VERSION ""

NS_ :

BS_:

BU_: HV HV HV CELLBOARD CELLBOARD HANDCART CELLBOARD HV BMS_HV MAINBOARD HV BMS_HV HV CELLBOARD BMS_HV MAINBOARD HV HANDCART MAINBOARD HV HANDCART HV MAINBOARD HANDCART HV BMS_HV CELLBOARD HV BMS_HV HV BMS_HV HV HANDCART HV HANDCART HV HV HANDCART HV BMS_HV HV BMS_HV HV HV HV BMS_HV HV HANDCART HV BMS_HV HANDCART CELLBOARD HV HV HV MAINBOARD HANDCART HV MAINBOARD HV HANDCART BMS_HV
VAL_TABLE_ _B9_Voltage_Channels 3 "3_Channels" 0 "0_Channels" ;
VAL_TABLE_ _B9_Supply_Voltage 1 "12__24_V_nominal_supply_voltage" ;
VAL_TABLE_ _B9_Current 2500 "2500_A" 1000 "1000_A" 500 "500_A" 300 "300_A" 100 "100_A" ;
VAL_TABLE_ _B9_Device_Type 2 "IVT_S" 1 "IVT_Mod" ;
VAL_TABLE_ VtDevice_Com 2 "CAN_2___not_terminated" 1 "CAN_1___terminated" 0 "none" ;
VAL_TABLE_ VtDevice_TOI 3 "I" ;
VAL_TABLE_ VtResetErrorLogdata 7 "Reset_error_current_implausible" 6 "Reset_error_Vref" 5 "Reset_error_Underflow_ADC_ch2" 4 "Reset_error_Overflow_ADC_ch2" 3 "Reset_error_Underflow_ADC_ch1" 2 "Reset_error_Overflow_ADC_ch1" 1 "Reset_error_ADC_interrupt" 0 "Reset_all_measurement_errors" ;
VAL_TABLE_ VtID_Result 8 "Vt_Result_Wh" 7 "Vt_Result_Ah" 6 "Vt_Result_W" 5 "Vt_Result_T" 4 "Vt_Result_U3" 3 "Vt_Result_U2" 2 "Vt_Result_U1" 1 "Vt_Result_I" 0 "Vt_Result_inaktive" ;
VAL_TABLE_ VtID_Cmd 54 "Set_THRESHOLD_neg" 53 "Set_THRESHOLD_pos" 52 "Set_MODE" 51 "START_OC_TEST" 50 "STORE" 49 "TRIGGER" 48 "Reset_Err_Log" 39 "Set_MODE_Result_Wh" 38 "Set_MODE_Result_Ah" 37 "Set_MODE_Result_W" 36 "Set_MODE_Result_T" 35 "Set_MODE_Result_U3" 34 "Set_MODE_Result_U2" 33 "Set_MODE_Result_U1" 32 "Set_MODE_Result_I" 31 "Set_CAN_ID_Cmd" 29 "Set_CAN_ID_Response" 23 "Set_CAN_ID_Result_Wh" 22 "Set_CAN_ID_Result_Ah" 21 "Set_CAN_ID_Result_W" 20 "Set_CAN_ID_Result_T" 19 "Set_CAN_ID_Result_U3" 18 "Set_CAN_ID_Result_U2" 17 "Set_CAN_ID_Result_U1" 16 "Set_CAN_ID_Result_I" ;
VAL_TABLE_ VtTriggerMode 2 "CYCLIC" 1 "TRIGGERED" 0 "DISABLED" ;
VAL_TABLE_ VtRunMode 1 "START" 0 "STOP" ;
VAL_TABLE_ VtID_Response 149 "ARTICLE_NUMBER" 148 "SERIAL_NUMBER" 147 "SW_VERSION" 146 "DEVICE_ID" 145 "STATUS" 143 "CAN_ID" 142 "STORE_to_default" 134 "START_OC_TEST" 133 "Description_for_the_value_'0x85'" 132 "THRESHOLD" 131 "CONFIG" 130 "MODE" 129 "STORE" 128 "TRIGGER" ;

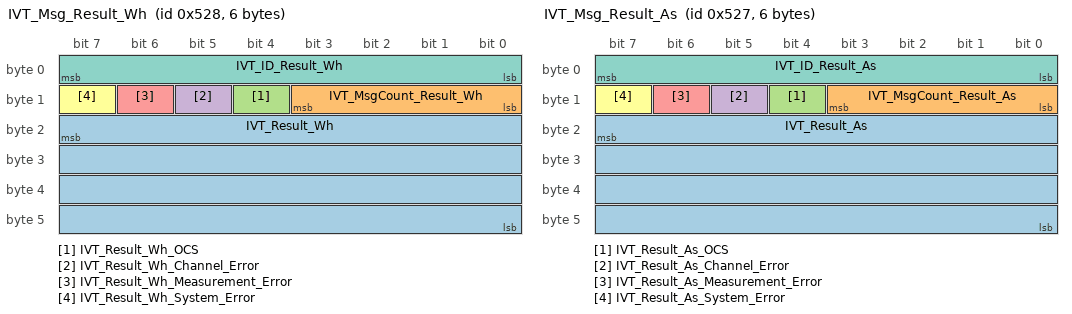
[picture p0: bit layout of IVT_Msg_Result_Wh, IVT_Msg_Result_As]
BO_ 1320 IVT_Msg_Result_Wh: 6 IVT_Mod
 SG_ IVT_Result_Wh : 23|32@0- (1,0) [-2147483648|2147483647] "Wh"  Host
 SG_ IVT_MsgCount_Result_Wh : 11|4@0+ (1,0) [0|0] ""  Host
 SG_ IVT_Result_Wh_OCS : 12|1@0+ (1,0) [0|0] "" Vector__XXX
 SG_ IVT_Result_Wh_Channel_Error : 13|1@0+ (1,0) [0|0] "" Vector__XXX
 SG_ IVT_Result_Wh_Measurement_Error : 14|1@0+ (1,0) [0|0] "" Vector__XXX
 SG_ IVT_Result_Wh_System_Error : 15|1@0+ (1,0) [0|0] "" Vector__XXX
 SG_ IVT_ID_Result_Wh : 7|8@0+ (1,0) [7|7] ""  Host

BO_ 1319 IVT_Msg_Result_As: 6 IVT_Mod
 SG_ IVT_Result_As : 23|32@0- (1,0) [-21474836478|2147483647] "As"  Host
 SG_ IVT_MsgCount_Result_As : 11|4@0+ (1,0) [0|0] ""  Host
 SG_ IVT_Result_As_OCS : 12|1@0+ (1,0) [0|0] "" Vector__XXX
 SG_ IVT_Result_As_Channel_Error : 13|1@0+ (1,0) [0|0] "" Vector__XXX
 SG_ IVT_Result_As_Measurement_Error : 14|1@0+ (1,0) [0|0] "" Vector__XXX
 SG_ IVT_Result_As_System_Error : 15|1@0+ (1,0) [0|0] "" Vector__XXX
 SG_ IVT_ID_Result_As : 7|8@0+ (1,0) [6|6] ""  Host

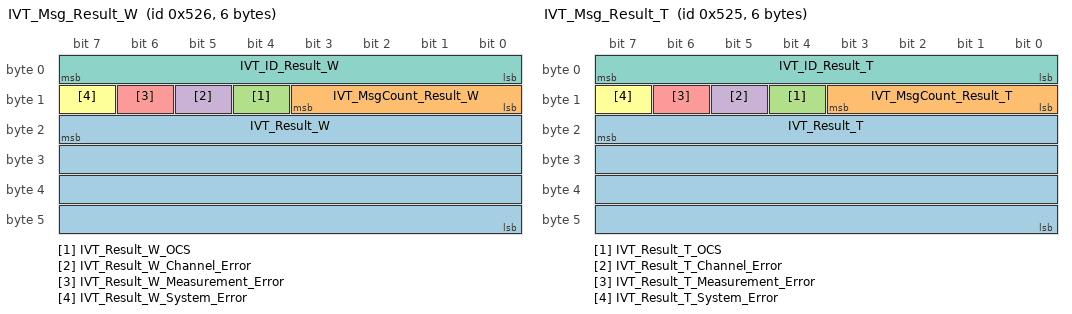
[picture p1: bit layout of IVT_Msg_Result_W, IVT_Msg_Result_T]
BO_ 1318 IVT_Msg_Result_W: 6 IVT_Mod
 SG_ IVT_Result_W : 23|32@0- (1,0) [-2147483648|2147483647] "W"  Host
 SG_ IVT_MsgCount_Result_W : 11|4@0+ (1,0) [0|0] ""  Host
 SG_ IVT_Result_W_OCS : 12|1@0+ (1,0) [0|0] "" Vector__XXX
 SG_ IVT_Result_W_Channel_Error : 13|1@0+ (1,0) [0|0] "" Vector__XXX
 SG_ IVT_Result_W_Measurement_Error : 14|1@0+ (1,0) [0|0] "" Vector__XXX
 SG_ IVT_Result_W_System_Error : 15|1@0+ (1,0) [0|0] "" Vector__XXX
 SG_ IVT_ID_Result_W : 7|8@0+ (1,0) [5|5] ""  Host

BO_ 1297 IVT_Msg_Response: 8 IVT_Mod
 SG_ _BA_Resp_SW_Ver_Internal m186 : 63|8@0+ (1,0) [0|0] "" Vector__XXX
 SG_ _B9_Resp_Device_V_supply m185 : 55|8@0+ (1,0) [0|0] "V" Vector__XXX
 SG_ _BA_Resp_SW_Ver_Day m186 : 55|8@0+ (1,0) [0|0] "" Vector__XXX
 SG_ _B9_Resp_Device_Com m185 : 47|8@0+ (1,0) [0|0] "" Vector__XXX
 SG_ _BA_Resp_SW_Ver_Month m186 : 40|8@1- (1,0) [0|0] "" Vector__XXX
 SG_ _B9_Resp_Device_TOI m185 : 39|8@0+ (1,0) [0|0] "" Vector__XXX
 SG_ _BA_Resp_SW_Ver_Vear m186 : 39|8@0+ (1,0) [0|0] "" Vector__XXX
 SG_ _B9_Resp_Device_Voltage_chan m185 : 27|4@0+ (1,0) [0|0] "" Vector__XXX
 SG_ _B6_Resp_OC_Neg_Reset_Threshold m182 : 31|16@0- (1,0) [0|0] "" Vector__XXX
 SG_ _B5_Resp_OC_Pos_Reset_Threshold m181 : 31|16@0- (1,0) [0|0] "" Vector__XXX
 SG_ _B4_Resp_Code_Level m180 : 31|16@0+ (1,0) [0|0] "" Vector__XXX
 SG_ _B0_Resp_Reset_Device_SN m176 : 31|32@0+ (1,0) [0|0] "" Vector__XXX
 SG_ _9F_Resp_Can_ID_SN_Response m159 : 31|32@0+ (1,0) [0|0] "" Vector__XXX
 SG_ _9D_Resp_Can_ID_SN_Command m157 : 31|32@0+ (1,0) [0|0] "" Vector__XXX
 SG_ _97_Resp_Can_ID_SN_Wh m151 : 31|32@0+ (1,0) [0|0] "" Vector__XXX
 SG_ _96_Resp_Can_ID_SN_As m150 : 31|32@0+ (1,0) [0|0] "" Vector__XXX
 SG_ _95_Resp_Can_ID_SN_W m149 : 31|32@0+ (1,0) [0|0] "" Vector__XXX
 SG_ _94_Resp_Can_ID_SN_T m148 : 31|32@0+ (1,0) [0|0] "" Vector__XXX
 SG_ _93_Resp_Can_ID_SN_U3 m147 : 31|32@0+ (1,0) [0|0] "" Vector__XXX
 SG_ _92_Resp_Can_ID_SN_U2 m146 : 31|32@0+ (1,0) [0|0] "" Vector__XXX
 SG_ _91_Resp_Can_ID_SN_U1 m145 : 31|32@0+ (1,0) [0|0] "" Vector__XXX
 SG_ _90_Resp_Can_ID_SN_I m144 : 31|32@0+ (1,0) [0|0] "" Vector__XXX
 SG_ _BA_Resp_SW_Ver_Revision m186 : 31|8@0+ (1,0) [0|0] "" Vector__XXX
 SG_ _BF_Restart_Alive_SN m191 : 31|32@0+ (1,0) [0|0] "" Vector__XXX
 SG_ _B4_Resp_Startup_Mode m180 : 16|1@0+ (1,0) [0|0] "" Vector__XXX
 SG_ _B1_00_Trigger_I m177 : 16|1@0+ (1,0) [0|0] "" Vector__XXX
 SG_ _B1_01_Trigger_U1 m177 : 17|1@0+ (1,0) [0|0] "" Vector__XXX
 SG_ _B1_02_Trigger_U2 m177 : 18|1@0+ (1,0) [0|0] "" Vector__XXX
 SG_ _B1_03_Trigger_U3 m177 : 19|1@0+ (1,0) [0|0] "" Vector__XXX
 SG_ _B1_04_Trigger_T m177 : 20|1@0+ (1,0) [0|0] "" Vector__XXX
 SG_ _B1_05_Trigger_W m177 : 21|1@0+ (1,0) [0|0] "" Vector__XXX
 SG_ _B1_06_Trigger_As m177 : 22|1@0+ (1,0) [0|0] "" Vector__XXX
 SG_ _A7_Resp_CycleTime_WH m167 : 23|16@0+ (1,0) [0|0] "ms" Vector__XXX
 SG_ _A6_Resp_CycleTime_As m166 : 23|16@0+ (1,0) [0|0] "ms" Vector__XXX
 SG_ _A5_Resp_CycleTime_W m165 : 23|16@0+ (1,0) [0|0] "ms" Vector__XXX
 SG_ _A4_Resp_CycleTime_T m164 : 23|16@0+ (1,0) [0|0] "ms" Vector__XXX
 SG_ _A3_Resp_CycleTime_U3 m163 : 23|16@0+ (1,0) [0|0] "ms" Vector__XXX
 SG_ _A2_Resp_CycleTime_U2 m162 : 23|16@0+ (1,0) [0|0] "ms" Vector__XXX
 SG_ _A1_Resp_CycleTime_U1 m161 : 23|16@0+ (1,0) [0|0] "ms" Vector__XXX
 SG_ _A0_Resp_CycleTime_I m160 : 23|16@0+ (1,0) [0|0] "ms" Vector__XXX
 SG_ _83_Resp_LogData_Counter m131 : 23|48@0+ (1,0) [0|0] "" Vector__XXX
 SG_ _82_Resp_AllLogData_Counter m130 : 23|48@0+ (1,0) [0|0] "" Vector__XXX
 SG_ _81_Resp_SystemError_Count_Mask m129 : 23|16@0+ (1,0) [0|0] "" Vector__XXX
 SG_ _80_Resp_MeasError_Count_Mask m128 : 23|16@0+ (1,0) [0|0] "" Vector__XXX
 SG_ _B9_Resp_Device_current m185 : 23|12@0+ (1,0) [0|0] "A" Vector__XXX
 SG_ _BA_Resp_SW_Ver_Minor m186 : 23|8@0+ (1,0) [0|0] "" Vector__XXX
 SG_ _B2_Resp_Store_Device_SN m178 : 23|32@0+ (1,0) [0|0] "" Vector__XXX
 SG_ _B1_07_Trigger_WH m177 : 23|1@0+ (1,0) [0|0] "" Vector__XXX
 SG_ _B4_Resp_Actual_Mode m180 : 8|1@0+ (1,0) [0|0] "" Vector__XXX
 SG_ _A7_Resp_TriggerMode_WH m167 : 9|2@0+ (1,0) [0|2] "" Vector__XXX
 SG_ _A6_Resp_TriggerMode_As m166 : 9|2@0+ (1,0) [0|2] "" Vector__XXX
 SG_ _A5_Resp_TriggerMode_W m165 : 9|2@0+ (1,0) [0|2] "" Vector__XXX
 SG_ _A4_Resp_TriggerMode_T m164 : 9|2@0+ (1,0) [0|2] "" Vector__XXX
 SG_ _A3_Resp_TriggerMode_U3 m163 : 9|2@0+ (1,0) [0|2] "" Vector__XXX
 SG_ _A2_Resp_TriggerMode_U2 m162 : 9|2@0+ (1,0) [0|2] "" Vector__XXX
 SG_ _A1_Resp_TriggerMode_U1 m161 : 9|2@0+ (1,0) [0|2] "" Vector__XXX
 SG_ _A0_Resp_TriggerMode_I m160 : 9|2@0+ (1,0) [0|2] "" Vector__XXX
 SG_ _A7_Resp_Endianess_WH m167 : 14|1@0+ (1,0) [0|0] "" Vector__XXX
 SG_ _A6_Resp_Endianess_As m166 : 14|1@0+ (1,0) [0|0] "" Vector__XXX
 SG_ _A5_Resp_Endianess_W m165 : 14|1@0+ (1,0) [0|0] "" Vector__XXX
 SG_ _A4_Resp_Endianess_T m164 : 14|1@0+ (1,0) [0|0] "" Vector__XXX
 SG_ _A3_Resp_Endianess_U3 m163 : 14|1@0+ (1,0) [0|0] "" Vector__XXX
 SG_ _A2_Resp_Endianess_U2 m162 : 14|1@0+ (1,0) [0|0] "" Vector__XXX
 SG_ _A1_Resp_Endianess_U1 m161 : 14|1@0+ (1,0) [0|0] "" Vector__XXX
 SG_ _A0_Resp_Endianess_I m160 : 14|1@0+ (1,0) [0|0] "" Vector__XXX
 SG_ _BC_Resp_Art_N m188 : 15|56@0+ (1,0) [0|0] "" Vector__XXX
 SG_ _BB_Resp_Serien_Nr m187 : 15|32@0+ (1,0) [0|0] "" Vector__XXX
 SG_ _BA_Resp_SW_Ver_Major_HW m186 : 15|8@0+ (1,0) [0|0] "" Vector__XXX
 SG_ _B9_Resp_Device_type m185 : 15|8@0+ (1,0) [0|0] "" Vector__XXX
 SG_ _B6_Resp_OC_Neg_Set_Threshold m182 : 15|16@0- (1,0) [0|0] "" Vector__XXX
 SG_ _B5_Resp_OC_Pos_Set_Threshold m181 : 15|16@0- (1,0) [0|0] "" Vector__XXX
 SG_ _B3_Resp_Oc_Test_Time m179 : 15|16@0+ (1,0) [0|65535] "ms" Vector__XXX
 SG_ _B2_Resp_Store_dummy m178 : 15|8@0+ (1,0) [0|0] "" Vector__XXX
 SG_ _B0_Resp_Reset_Item m176 : 15|16@0+ (1,0) [0|0] "" Vector__XXX
 SG_ _A7_Resp_Sign_WH m167 : 15|1@0+ (1,0) [0|0] "" Vector__XXX
 SG_ _A6_Resp_Sign_As m166 : 15|1@0+ (1,0) [0|0] "" Vector__XXX
 SG_ _A5_Resp_Sign_W m165 : 15|1@0+ (1,0) [0|0] "" Vector__XXX
 SG_ _A4_Resp_Sign_T m164 : 15|1@0+ (1,0) [0|0] "" Vector__XXX
 SG_ _A3_Resp_Sign_U3 m163 : 15|1@0+ (1,0) [0|0] "" Vector__XXX
 SG_ _A2_Resp_Sign_U2 m162 : 15|1@0+ (1,0) [0|0] "" Vector__XXX
 SG_ _A1_Resp_Sign_U1 m161 : 15|1@0+ (1,0) [0|0] "" Vector__XXX
 SG_ _A0_Resp_Sign_I m160 : 15|1@0+ (1,0) [0|0] "" Vector__XXX
 SG_ _9F_Resp_Can_ID_val_Response m159 : 15|16@0+ (1,0) [0|0] "" Vector__XXX
 SG_ _9D_Resp_Can_ID_val_Command m157 : 15|16@0+ (1,0) [0|0] "" Vector__XXX
 SG_ _97_Resp_Can_ID_val_Wh m151 : 15|16@0+ (1,0) [0|0] "" Vector__XXX
 SG_ _96_Resp_Can_ID_val_As m150 : 15|16@0+ (1,0) [0|0] "" Vector__XXX
 SG_ _95_Resp_Can_ID_val_W m149 : 15|16@0+ (1,0) [0|0] "" Vector__XXX
 SG_ _94_Resp_Can_ID_val_T m148 : 15|16@0+ (1,0) [0|0] "" Vector__XXX
 SG_ _93_Resp_Can_ID_val_U3 m147 : 15|16@0+ (1,0) [0|0] "" Vector__XXX
 SG_ _92_Resp_Can_ID_val_U2 m146 : 15|16@0+ (1,0) [0|0] "" Vector__XXX
 SG_ _91_Resp_Can_ID_val_U1 m145 : 15|16@0+ (1,0) [0|0] "" Vector__XXX
 SG_ _90_Resp_Can_ID_val_I m144 : 15|16@0+ (1,0) [0|0] "" Vector__XXX
 SG_ _83_Resp_LogData_Item m131 : 15|8@0+ (1,0) [0|0] "" Vector__XXX
 SG_ _82_Resp_AllLogData_Item m130 : 15|8@0+ (1,0) [0|0] "" Vector__XXX
 SG_ _81_Resp_SystemError_Item m129 : 15|8@0+ (1,0) [0|0] "" Vector__XXX
 SG_ _80_Resp_MeasError_Item m128 : 15|8@0+ (1,0) [0|0] "" Vector__XXX
 SG_ _BF_Restart_Alive_Cmd_ID m191 : 15|16@0+ (1,0) [0|0] "" Vector__XXX
 SG_ _FF_Wrong_Command m255 : 15|8@0+ (1,0) [0|0] "" Vector__XXX
 SG_ _B1_Trigger_spare m177 : 15|8@0+ (1,0) [0|0] "" Vector__XXX
 SG_ IVT_ID_Response M : 7|8@0+ (1,0) [0|0] ""  Host

BO_ 1317 IVT_Msg_Result_T: 6 IVT_Mod
 SG_ IVT_Result_T : 23|32@0- (0.1,0) [-2147483648|2147483647] "Â°C"  Host
 SG_ IVT_MsgCount_Result_T : 11|4@0+ (1,0) [0|0] ""  Host
 SG_ IVT_Result_T_OCS : 12|1@0+ (1,0) [0|0] "" Vector__XXX
 SG_ IVT_Result_T_Channel_Error : 13|1@0+ (1,0) [0|0] "" Vector__XXX
 SG_ IVT_Result_T_Measurement_Error : 14|1@0+ (1,0) [0|0] "" Vector__XXX
 SG_ IVT_Result_T_System_Error : 15|1@0+ (1,0) [0|0] "" Vector__XXX
 SG_ IVT_ID_Result_T : 7|8@0+ (1,0) [4|4] ""  Host

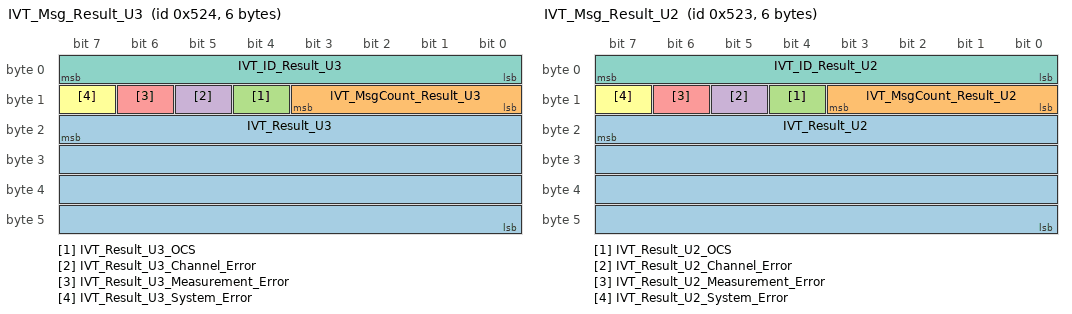
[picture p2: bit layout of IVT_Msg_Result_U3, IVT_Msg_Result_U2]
BO_ 1316 IVT_Msg_Result_U3: 6 IVT_Mod
 SG_ IVT_Result_U3 : 23|32@0- (1,0) [-2147483648|2147483647] "mV"  Host
 SG_ IVT_MsgCount_Result_U3 : 11|4@0+ (1,0) [0|0] ""  Host
 SG_ IVT_Result_U3_OCS : 12|1@0+ (1,0) [0|0] "" Vector__XXX
 SG_ IVT_Result_U3_Channel_Error : 13|1@0+ (1,0) [0|0] "" Vector__XXX
 SG_ IVT_Result_U3_Measurement_Error : 14|1@0+ (1,0) [0|0] "" Vector__XXX
 SG_ IVT_Result_U3_System_Error : 15|1@0+ (1,0) [0|0] "" Vector__XXX
 SG_ IVT_ID_Result_U3 : 7|8@0+ (1,0) [3|3] ""  Host

BO_ 1315 IVT_Msg_Result_U2: 6 IVT_Mod
 SG_ IVT_Result_U2 : 23|32@0- (1,0) [-2147483648|2147483647] "mV"  Host
 SG_ IVT_MsgCount_Result_U2 : 11|4@0+ (1,0) [0|0] ""  Host
 SG_ IVT_Result_U2_OCS : 12|1@0+ (1,0) [0|0] "" Vector__XXX
 SG_ IVT_Result_U2_Channel_Error : 13|1@0+ (1,0) [0|0] "" Vector__XXX
 SG_ IVT_Result_U2_Measurement_Error : 14|1@0+ (1,0) [0|0] "" Vector__XXX
 SG_ IVT_Result_U2_System_Error : 15|1@0+ (1,0) [0|0] "" Vector__XXX
 SG_ IVT_ID_Result_U2 : 7|8@0+ (1,0) [2|2] ""  Host

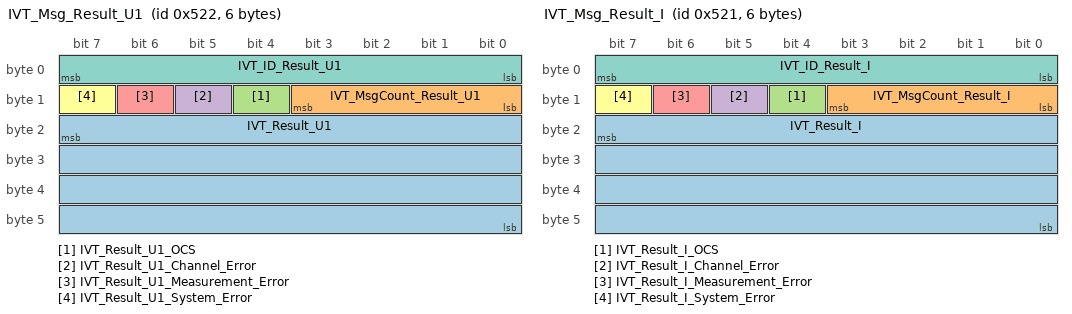
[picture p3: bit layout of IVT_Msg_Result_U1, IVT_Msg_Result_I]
BO_ 1314 IVT_Msg_Result_U1: 6 IVT_Mod
 SG_ IVT_Result_U1 : 23|32@0- (1,0) [-2147483648|2147483647] "mV"  Host
 SG_ IVT_MsgCount_Result_U1 : 11|4@0+ (1,0) [0|0] ""  Host
 SG_ IVT_Result_U1_OCS : 12|1@0+ (1,0) [0|0] "" Vector__XXX
 SG_ IVT_Result_U1_Channel_Error : 13|1@0+ (1,0) [0|0] "" Vector__XXX
 SG_ IVT_Result_U1_Measurement_Error : 14|1@0+ (1,0) [0|0] "" Vector__XXX
 SG_ IVT_Result_U1_System_Error : 15|1@0+ (1,0) [0|0] "" Vector__XXX
 SG_ IVT_ID_Result_U1 : 7|8@0+ (1,0) [1|1] ""  Host

BO_ 1313 IVT_Msg_Result_I: 6 IVT_Mod
 SG_ IVT_Result_I : 23|32@0- (1,0) [-2147483648|2147483647] "mA"  Host
 SG_ IVT_MsgCount_Result_I : 11|4@0+ (1,0) [0|0] ""  Host
 SG_ IVT_Result_I_OCS : 12|1@0+ (1,0) [0|0] "" Vector__XXX
 SG_ IVT_Result_I_Channel_Error : 13|1@0+ (1,0) [0|0] "" Vector__XXX
 SG_ IVT_Result_I_Measurement_Error : 14|1@0+ (1,0) [0|0] "" Vector__XXX
 SG_ IVT_Result_I_System_Error : 15|1@0+ (1,0) [0|0] "" Vector__XXX
 SG_ IVT_ID_Result_I : 7|8@0+ (1,0) [0|0] ""  Host

BO_ 1041 IVT_Msg_Cmd: 8 Host
 SG_ _5F_Get_Can_ID_SN_Response m95 : 31|32@0+ (1,0) [0|0] "" Vector__XXX
 SG_ _5D_Get_Can_ID_SN_Command m93 : 31|32@0+ (1,0) [0|0] "" Vector__XXX
 SG_ _57_Get_Can_ID_SN_Wh m87 : 31|32@0+ (1,0) [0|0] "" Vector__XXX
 SG_ _56_Get_Can_ID_SN_As m86 : 31|32@0+ (1,0) [0|0] "" Vector__XXX
 SG_ _55_Get_Can_ID_SN_W m85 : 31|32@0+ (1,0) [0|0] "" Vector__XXX
 SG_ _54_Get_Can_ID_SN_T m84 : 31|32@0+ (1,0) [0|0] "" Vector__XXX
 SG_ _53_Get_Can_ID_SN_U3 m83 : 31|32@0+ (1,0) [0|0] "" Vector__XXX
 SG_ _52_Get_Can_ID_SN_U2 m82 : 31|32@0+ (1,0) [0|0] "" Vector__XXX
 SG_ _51_Get_Can_ID_SN_U1 m81 : 31|32@0+ (1,0) [0|0] "" Vector__XXX
 SG_ _50_Get_Can_ID_SN_I m80 : 31|32@0+ (1,0) [0|0] "" Vector__XXX
 SG_ _36_OC_Neg_Reset_Threshold m54 : 31|16@0- (1,0) [0|0] "A" Vector__XXX
 SG_ _35_OC_Pos_Reset_Threshold m53 : 31|16@0- (1,0) [0|0] "A" Vector__XXX
 SG_ _34_Code_Level m52 : 31|16@0+ (1,0) [0|0] "" Vector__XXX
 SG_ _30_Reset_Device_SN m48 : 31|32@0+ (1,0) [0|0] "" Vector__XXX
 SG_ _1F_Set_Can_ID_SN_Response m31 : 31|32@0+ (1,0) [0|0] "" Vector__XXX
 SG_ _1D_Set_Can_ID_SN_Command m29 : 31|32@0+ (1,0) [0|0] "" Vector__XXX
 SG_ _17_Set_Can_ID_SN_Wh m23 : 31|32@0+ (1,0) [0|0] "" Vector__XXX
 SG_ _16_Set_Can_ID_SN_As m22 : 31|32@0+ (1,0) [0|0] "" Vector__XXX
 SG_ _15_Set_Can_ID_SN_W m21 : 31|32@0+ (1,0) [0|0] "" Vector__XXX
 SG_ _14_Set_Can_ID_SN_T m20 : 31|32@0+ (1,0) [0|0] "" Vector__XXX
 SG_ _13_Set_Can_ID_SN_U3 m19 : 31|32@0+ (1,0) [0|0] "" Vector__XXX
 SG_ _12_Set_Can_ID_SN_U2 m18 : 31|32@0+ (1,0) [0|0] "" Vector__XXX
 SG_ _11_Set_Can_ID_SN_U1 m17 : 31|32@0+ (1,0) [0|0] "" Vector__XXX
 SG_ _10_Set_Can_ID_SN_I m16 : 31|32@0+ (1,0) [0|0] "" Vector__XXX
 SG_ _34_Startup_Mode m52 : 16|1@0+ (1,0) [0|0] "" Vector__XXX
 SG_ _31_00_Trigger_I m49 : 16|1@0+ (1,0) [0|0] "" Vector__XXX
 SG_ _31_01_Trigger_U1 m49 : 17|1@0+ (1,0) [0|0] "" Vector__XXX
 SG_ _31_02_Trigger_U2 m49 : 18|1@0+ (1,0) [0|0] "" Vector__XXX
 SG_ _31_03_Trigger_U3 m49 : 19|1@0+ (1,0) [0|0] "" Vector__XXX
 SG_ _31_04_Trigger_T m49 : 20|1@0+ (1,0) [0|0] "" Vector__XXX
 SG_ _31_05_Trigger_W m49 : 21|1@0+ (1,0) [0|0] "" Vector__XXX
 SG_ _31_06_Trigger_As m49 : 22|1@0+ (1,0) [0|0] "" Vector__XXX
 SG_ _27_Conf_CycleTime_WH m39 : 23|16@0+ (1,0) [0|0] "ms" Vector__XXX
 SG_ _26_Conf_CycleTime_As m38 : 23|16@0+ (1,0) [0|0] "ms" Vector__XXX
 SG_ _25_Conf_CycleTime_W m37 : 23|16@0+ (1,0) [0|0] "ms" Vector__XXX
 SG_ _24_Conf_CycleTime_T m36 : 23|16@0+ (1,0) [0|0] "ms" Vector__XXX
 SG_ _23_Conf_CycleTime_U3 m35 : 23|16@0+ (1,0) [0|0] "ms" Vector__XXX
 SG_ _22_Conf_CycleTime_U2 m34 : 23|16@0+ (1,0) [0|0] "ms" Vector__XXX
 SG_ _21_Conf_CycleTime_U1 m33 : 23|16@0+ (1,0) [0|0] "ms" Vector__XXX
 SG_ _20_Conf_CycleTime_I m32 : 23|16@0+ (1,0) [0|0] "ms" Vector__XXX
 SG_ _31_07_Trigger_WH m49 : 23|1@0+ (1,0) [0|0] "" Vector__XXX
 SG_ _34_Actual_Mode m52 : 8|1@0+ (1,0) [0|0] "" Vector__XXX
 SG_ _27_Conf_TriggerMode_WH m39 : 9|2@0+ (1,0) [0|2] "" Vector__XXX
 SG_ _26_Conf_TriggerMode_As m38 : 9|2@0+ (1,0) [0|2] "" Vector__XXX
 SG_ _25_Conf_TriggerMode_W m37 : 9|2@0+ (1,0) [0|2] "" Vector__XXX
 SG_ _24_Conf_TriggerMode_T m36 : 9|2@0+ (1,0) [0|2] "" Vector__XXX
 SG_ _23_Conf_TriggerMode_U3 m35 : 9|2@0+ (1,0) [0|2] "" Vector__XXX
 SG_ _22_Conf_TriggerMode_U2 m34 : 9|2@0+ (1,0) [0|2] "" Vector__XXX
 SG_ _21_Conf_TriggerMode_U1 m33 : 9|2@0+ (1,0) [0|2] "" Vector__XXX
 SG_ _20_Conf_TriggerMode_I m32 : 9|2@0+ (1,0) [0|2] "" Vector__XXX
 SG_ _27_Conf_Endianess_WH m39 : 14|1@0+ (1,0) [0|0] "" Vector__XXX
 SG_ _26_Conf_Endianess_As m38 : 14|1@0+ (1,0) [0|0] "" Vector__XXX
 SG_ _25_Conf_Endianess_W m37 : 14|1@0+ (1,0) [0|0] "" Vector__XXX
 SG_ _24_Conf_Endianess_T m36 : 14|1@0+ (1,0) [0|0] "" Vector__XXX
 SG_ _23_Conf_Endianess_U3 m35 : 14|1@0+ (1,0) [0|0] "" Vector__XXX
 SG_ _22_Conf_Endianess_U2 m34 : 14|1@0+ (1,0) [0|0] "" Vector__XXX
 SG_ _21_Conf_Endianess_U1 m33 : 14|1@0+ (1,0) [0|0] "" Vector__XXX
 SG_ _20_Conf_Endianess_I m32 : 14|1@0+ (1,0) [0|0] "" Vector__XXX
 SG_ _7C_Get_Art_Nr_dummy m124 : 15|8@0+ (1,0) [0|0] "" Vector__XXX
 SG_ _7B_Get_Serien_Nr_dummy m123 : 15|8@0+ (1,0) [0|0] "" Vector__XXX
 SG_ _7A_Get_SW_Version_dummy m122 : 15|8@0+ (1,0) [0|0] "" Vector__XXX
 SG_ _79_Get_Device_Id_dummy m121 : 15|8@0+ (1,0) [0|0] "" Vector__XXX
 SG_ _76_Get_OC_Neg_dummy m118 : 15|8@0+ (1,0) [0|0] "" Vector__XXX
 SG_ _75_Get_OC_Pos_dummy m117 : 15|8@0+ (1,0) [0|0] "" Vector__XXX
 SG_ _74_Get_Mode_dummy m116 : 15|8@0+ (1,0) [0|0] "" Vector__XXX
 SG_ _73_Get_OC_Test_dummy m115 : 15|8@0+ (1,0) [0|0] "" Vector__XXX
 SG_ _67_Get_Result_dummy_Wh m103 : 15|8@0+ (1,0) [0|0] "" Vector__XXX
 SG_ _66_Get_Result_dummy_As m102 : 15|8@0+ (1,0) [0|0] "" Vector__XXX
 SG_ _65_Get_Result_dummy_W m101 : 15|8@0+ (1,0) [0|0] "" Vector__XXX
 SG_ _64_Get_Result_dummy_T m100 : 15|8@0+ (1,0) [0|0] "" Vector__XXX
 SG_ _63_Get_Result_dummy_U3 m99 : 15|8@0+ (1,0) [0|0] "" Vector__XXX
 SG_ _62_Get_Result_dummy_U2 m98 : 15|8@0+ (1,0) [0|0] "" Vector__XXX
 SG_ _61_Get_Result_dummy_U1 m97 : 15|8@0+ (1,0) [0|0] "" Vector__XXX
 SG_ _60_Get_Result_dummy_I m96 : 15|8@0+ (1,0) [0|0] "" Vector__XXX
 SG_ _43_Get_LogData_Item m67 : 15|8@0+ (1,0) [0|0] "" Vector__XXX
 SG_ _42_Get_AllLogData_Item m66 : 15|8@0+ (1,0) [0|0] "" Vector__XXX
 SG_ _41_Get_SystemError_Item m65 : 15|8@0+ (1,0) [0|0] "" Vector__XXX
 SG_ _40_Get_MeasError_Item m64 : 15|8@0+ (1,0) [0|0] "" Vector__XXX
 SG_ _3F_Restart_Dummy m63 : 15|8@0+ (1,0) [0|0] "" Vector__XXX
 SG_ _3D_Restart_Default_Dummy m61 : 15|8@0+ (1,0) [0|0] "" Vector__XXX
 SG_ _3A_RESTART_to_Bitrate m58 : 15|8@0+ (1,0) [0|0] "" Vector__XXX
 SG_ _36_OC_Neg_Set_Threshold m54 : 15|16@0- (1,0) [0|0] "A" Vector__XXX
 SG_ _35_OC_Pos_Set_Threshold m53 : 15|16@0- (1,0) [0|0] "A" Vector__XXX
 SG_ _33_Oc_Test_Time m51 : 15|16@0+ (1,0) [0|65535] "ms" Vector__XXX
 SG_ _32_Store_dummy m50 : 15|8@0+ (1,0) [0|0] "" Vector__XXX
 SG_ _30_Reset_Item m48 : 15|16@0+ (1,0) [0|0] "" Vector__XXX
 SG_ _27_Conf_Sign_WH m39 : 15|1@0+ (1,0) [0|0] "" Vector__XXX
 SG_ _26_Conf_Sign_As m38 : 15|1@0+ (1,0) [0|0] "" Vector__XXX
 SG_ _25_Conf_Sign_W m37 : 15|1@0+ (1,0) [0|0] "" Vector__XXX
 SG_ _24_Conf_Sign_T m36 : 15|1@0+ (1,0) [0|0] "" Vector__XXX
 SG_ _23_Conf_Sign_U3 m35 : 15|1@0+ (1,0) [0|0] "" Vector__XXX
 SG_ _22_Conf_Sign_U2 m34 : 15|1@0+ (1,0) [0|0] "" Vector__XXX
 SG_ _21_Conf_Sign_U1 m33 : 15|1@0+ (1,0) [0|0] "" Vector__XXX
 SG_ _20_Conf_Sign_I m32 : 15|1@0+ (1,0) [0|0] "" Vector__XXX
 SG_ _1F_Set_Can_ID_val_Response m31 : 15|16@0+ (1,0) [0|2047] "" Vector__XXX
 SG_ _1D_Set_Can_ID_val_Command m29 : 15|16@0+ (1,0) [0|2047] "" Vector__XXX
 SG_ _17_Set_Can_ID_val_Wh m23 : 15|16@0+ (1,0) [0|2047] "" Vector__XXX
 SG_ _16_Set_Can_ID_val_As m22 : 15|16@0+ (1,0) [0|2047] "" Vector__XXX
 SG_ _15_Set_Can_ID_val_W m21 : 15|16@0+ (1,0) [0|2047] "" Vector__XXX
 SG_ _14_Set_Can_ID_val_T m20 : 15|16@0+ (1,0) [0|2047] "" Vector__XXX
 SG_ _13_Set_Can_ID_val_U3 m19 : 15|16@0+ (1,0) [0|2047] "" Vector__XXX
 SG_ _12_Set_Can_ID_val_U2 m18 : 15|16@0+ (1,0) [0|2047] "" Vector__XXX
 SG_ _11_Set_Can_ID_val_U1 m17 : 15|16@0+ (1,0) [0|2047] "" Vector__XXX
 SG_ _10_Set_Can_ID_val_I m16 : 15|16@0+ (1,0) [0|2047] ""  IVT_Mod
 SG_ _31_Trigger_spare m49 : 15|8@0+ (1,0) [0|0] "" Vector__XXX
 SG_ IVT_ID_Cmd M : 7|8@0+ (1,0) [0|0] ""  IVT_Mod

BO_ 1026 BOARD_STATUS: 4 Vector__XXX
 SG_ balancing_cells_CELL17 : 30|1@1+ (1,0) [0|1] "" Vector__XXX
 SG_ balancing_cells_CELL16 : 29|1@1+ (1,0) [0|1] "" Vector__XXX
 SG_ balancing_cells_CELL15 : 28|1@1+ (1,0) [0|1] "" Vector__XXX
 SG_ balancing_cells_CELL14 : 27|1@1+ (1,0) [0|1] "" Vector__XXX
 SG_ balancing_cells_CELL13 : 26|1@1+ (1,0) [0|1] "" Vector__XXX
 SG_ balancing_cells_CELL12 : 25|1@1+ (1,0) [0|1] "" Vector__XXX
 SG_ balancing_cells_CELL11 : 24|1@1+ (1,0) [0|1] "" Vector__XXX
 SG_ balancing_cells_CELL10 : 23|1@1+ (1,0) [0|1] "" Vector__XXX
 SG_ balancing_cells_CELL9 : 22|1@1+ (1,0) [0|1] "" Vector__XXX
 SG_ balancing_cells_CELL8 : 21|1@1+ (1,0) [0|1] "" Vector__XXX
 SG_ balancing_cells_CELL7 : 20|1@1+ (1,0) [0|1] "" Vector__XXX
 SG_ balancing_cells_CELL6 : 19|1@1+ (1,0) [0|1] "" Vector__XXX
 SG_ balancing_cells_CELL5 : 18|1@1+ (1,0) [0|1] "" Vector__XXX
 SG_ balancing_cells_CELL4 : 17|1@1+ (1,0) [0|1] "" Vector__XXX
 SG_ balancing_cells_CELL3 : 16|1@1+ (1,0) [0|1] "" Vector__XXX
 SG_ balancing_cells_CELL2 : 15|1@1+ (1,0) [0|1] "" Vector__XXX
 SG_ balancing_cells_CELL1 : 14|1@1+ (1,0) [0|1] "" Vector__XXX
 SG_ balancing_cells_CELL0 : 13|1@1+ (1,0) [0|1] "" Vector__XXX
 SG_ balancing_status : 12|1@1+ (1,0) [0|1] "" Vector__XXX
 SG_ errors_OPEN_WIRE : 11|1@1+ (1,0) [0|1] "" Vector__XXX
 SG_ errors_TEMP_COMM_5 : 10|1@1+ (1,0) [0|1] "" Vector__XXX
 SG_ errors_TEMP_COMM_4 : 9|1@1+ (1,0) [0|1] "" Vector__XXX
 SG_ errors_TEMP_COMM_3 : 8|1@1+ (1,0) [0|1] "" Vector__XXX
 SG_ errors_TEMP_COMM_2 : 7|1@1+ (1,0) [0|1] "" Vector__XXX
 SG_ errors_TEMP_COMM_1 : 6|1@1+ (1,0) [0|1] "" Vector__XXX
 SG_ errors_TEMP_COMM_0 : 5|1@1+ (1,0) [0|1] "" Vector__XXX
 SG_ errors_LTC_COMM : 4|1@1+ (1,0) [0|1] "" Vector__XXX
 SG_ errors_CAN_COMM : 3|1@1+ (1,0) [0|1] "" Vector__XXX
 SG_ cellboard_id : 0|3@1+ (1,0) [0|7] "" Vector__XXX

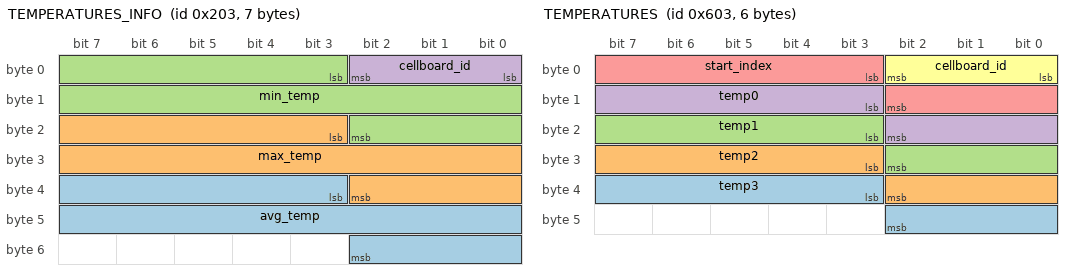
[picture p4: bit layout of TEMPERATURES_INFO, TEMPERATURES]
BO_ 515 TEMPERATURES_INFO: 7 Vector__XXX
 SG_ avg_temp : 35|16@1+ (0.0015259021896696422,-20) [-20|80] "" Vector__XXX
 SG_ max_temp : 19|16@1+ (0.0015259021896696422,-20) [-20|80] "" Vector__XXX
 SG_ min_temp : 3|16@1+ (0.0015259021896696422,-20) [-20|80] "" Vector__XXX
 SG_ cellboard_id : 0|3@1+ (1,0) [0|7] "" Vector__XXX

BO_ 1539 TEMPERATURES: 6 Vector__XXX
 SG_ temp3 : 35|8@1+ (0.39215686274509803,-20) [-20|80] "" Vector__XXX
 SG_ temp2 : 27|8@1+ (0.39215686274509803,-20) [-20|80] "" Vector__XXX
 SG_ temp1 : 19|8@1+ (0.39215686274509803,-20) [-20|80] "" Vector__XXX
 SG_ temp0 : 11|8@1+ (0.39215686274509803,-20) [-20|80] "" Vector__XXX
 SG_ start_index : 3|8@1+ (1,0) [0|255] "" Vector__XXX
 SG_ cellboard_id : 0|3@1+ (1,0) [0|7] "" Vector__XXX

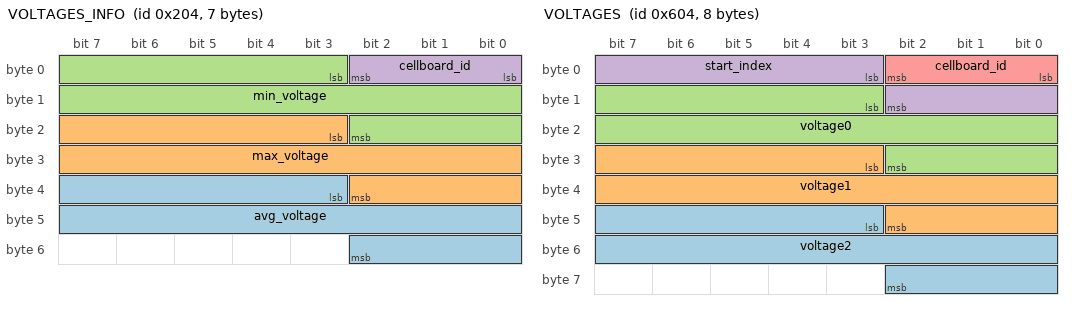
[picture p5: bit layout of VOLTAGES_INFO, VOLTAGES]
BO_ 516 VOLTAGES_INFO: 7 Vector__XXX
 SG_ avg_voltage : 35|16@1+ (7.629510948348211e-05,0) [0|5] "" Vector__XXX
 SG_ max_voltage : 19|16@1+ (7.629510948348211e-05,0) [0|5] "" Vector__XXX
 SG_ min_voltage : 3|16@1+ (7.629510948348211e-05,0) [0|5] "" Vector__XXX
 SG_ cellboard_id : 0|3@1+ (1,0) [0|7] "" Vector__XXX

BO_ 1540 VOLTAGES: 8 Vector__XXX
 SG_ voltage2 : 43|16@1+ (7.629510948348211e-05,0) [0|5] "" Vector__XXX
 SG_ voltage1 : 27|16@1+ (7.629510948348211e-05,0) [0|5] "" Vector__XXX
 SG_ voltage0 : 11|16@1+ (7.629510948348211e-05,0) [0|5] "" Vector__XXX
 SG_ start_index : 3|8@1+ (1,0) [0|255] "" Vector__XXX
 SG_ cellboard_id : 0|3@1+ (1,0) [0|7] "" Vector__XXX

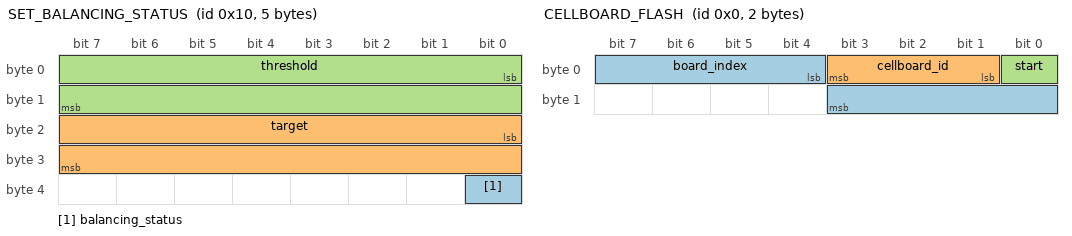
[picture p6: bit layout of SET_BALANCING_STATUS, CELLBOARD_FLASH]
BO_ 16 SET_BALANCING_STATUS: 5 Vector__XXX
 SG_ balancing_status : 32|1@1+ (1,0) [0|1] "" Vector__XXX
 SG_ target : 16|16@1+ (1,0) [0|65535] "" Vector__XXX
 SG_ threshold : 0|16@1+ (1,0) [0|65535] "" Vector__XXX

BO_ 5 FLASH_CELLBOARD_0_RX: 0 Vector__XXX

BO_ 6 FLASH_CELLBOARD_1_TX: 0 Vector__XXX

BO_ 7 FLASH_CELLBOARD_1_RX: 0 Vector__XXX

BO_ 8 FLASH_CELLBOARD_2_TX: 0 Vector__XXX

BO_ 9 FLASH_CELLBOARD_2_RX: 0 Vector__XXX

BO_ 10 FLASH_CELLBOARD_3_TX: 0 Vector__XXX

BO_ 11 FLASH_CELLBOARD_3_RX: 0 Vector__XXX

BO_ 12 FLASH_CELLBOARD_4_TX: 0 Vector__XXX

BO_ 13 FLASH_CELLBOARD_4_RX: 0 Vector__XXX

BO_ 14 FLASH_CELLBOARD_5_TX: 0 Vector__XXX

BO_ 15 FLASH_CELLBOARD_5_RX: 0 Vector__XXX

BO_ 0 CELLBOARD_FLASH: 2 Vector__XXX
 SG_ board_index : 4|8@1+ (1,0) [0|255] "" Vector__XXX
 SG_ cellboard_id : 1|3@1+ (1,0) [0|7] "" Vector__XXX
 SG_ start : 0|1@1+ (1,0) [0|1] "" Vector__XXX

BO_ 1 CELLBOARD_FLASH_TX: 0 Vector__XXX

BO_ 2 CELLBOARD_FLASH_RX: 0 Vector__XXX

BO_ 3 CELLBOARD_FLASH_REQUEST: 1 Vector__XXX
 SG_ cellboard_id : 1|3@1+ (1,0) [0|7] "" Vector__XXX
 SG_ mainboard : 0|1@1+ (1,0) [0|1] "" Vector__XXX

BO_ 4 CELLBOARD_FLASH_RESPONSE: 1 Vector__XXX
 SG_ ready : 3|1@1+ (1,0) [0|1] "" Vector__XXX
 SG_ cellboard_id : 0|3@1+ (1,0) [0|7] "" Vector__XXX

BO_ 1537 CELLBOARD_DISCOVERY: 1 Vector__XXX
 SG_ cellboard_id : 0|3@1+ (1,0) [0|7] "" Vector__XXX

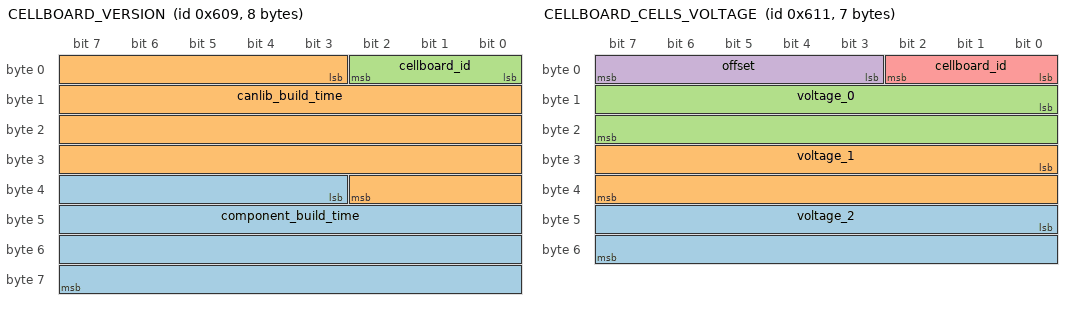
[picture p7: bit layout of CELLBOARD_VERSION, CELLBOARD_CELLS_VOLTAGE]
BO_ 1545 CELLBOARD_VERSION: 8 Vector__XXX
 SG_ component_build_time : 35|29@1+ (1,0) [0|536870911] "" Vector__XXX
 SG_ canlib_build_time : 3|32@1+ (1,0) [0|4294967295] "" Vector__XXX
 SG_ cellboard_id : 0|3@1+ (1,0) [0|7] "" Vector__XXX

BO_ 513 CELLBOARD_STATUS: 1 Vector__XXX
 SG_ status : 3|3@1+ (1,0) [0|7] "" Vector__XXX
 SG_ cellboard_id : 0|3@1+ (1,0) [0|7] "" Vector__XXX

BO_ 1553 CELLBOARD_CELLS_VOLTAGE: 7 Vector__XXX
 SG_ voltage_2 : 40|16@1+ (7.629510948348211e-05,0) [0|5] "" Vector__XXX
 SG_ voltage_1 : 24|16@1+ (7.629510948348211e-05,0) [0|5] "" Vector__XXX
 SG_ voltage_0 : 8|16@1+ (7.629510948348211e-05,0) [0|5] "" Vector__XXX
 SG_ offset : 3|5@1+ (1,0) [0|21] "" Vector__XXX
 SG_ cellboard_id : 0|3@1+ (1,0) [0|7] "" Vector__XXX

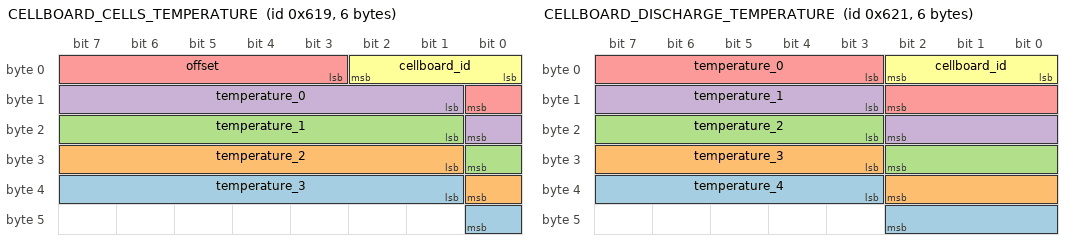
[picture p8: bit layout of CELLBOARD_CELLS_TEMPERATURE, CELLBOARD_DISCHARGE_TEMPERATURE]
BO_ 1561 CELLBOARD_CELLS_TEMPERATURE: 6 Vector__XXX
 SG_ temperature_3 : 33|8@1+ (0.49019607843137253,-25.0) [-25.0|100.0] "" Vector__XXX
 SG_ temperature_2 : 25|8@1+ (0.49019607843137253,-25.0) [-25.0|100.0] "" Vector__XXX
 SG_ temperature_1 : 17|8@1+ (0.49019607843137253,-25.0) [-25.0|100.0] "" Vector__XXX
 SG_ temperature_0 : 9|8@1+ (0.49019607843137253,-25.0) [-25.0|100.0] "" Vector__XXX
 SG_ offset : 3|6@1+ (1,0) [0|44] "" Vector__XXX
 SG_ cellboard_id : 0|3@1+ (1,0) [0|7] "" Vector__XXX

BO_ 1569 CELLBOARD_DISCHARGE_TEMPERATURE: 6 Vector__XXX
 SG_ temperature_4 : 35|8@1+ (0.49019607843137253,-25.0) [-25.0|100.0] "" Vector__XXX
 SG_ temperature_3 : 27|8@1+ (0.49019607843137253,-25.0) [-25.0|100.0] "" Vector__XXX
 SG_ temperature_2 : 19|8@1+ (0.49019607843137253,-25.0) [-25.0|100.0] "" Vector__XXX
 SG_ temperature_1 : 11|8@1+ (0.49019607843137253,-25.0) [-25.0|100.0] "" Vector__XXX
 SG_ temperature_0 : 3|8@1+ (0.49019607843137253,-25.0) [-25.0|100.0] "" Vector__XXX
 SG_ cellboard_id : 0|3@1+ (1,0) [0|7] "" Vector__XXX

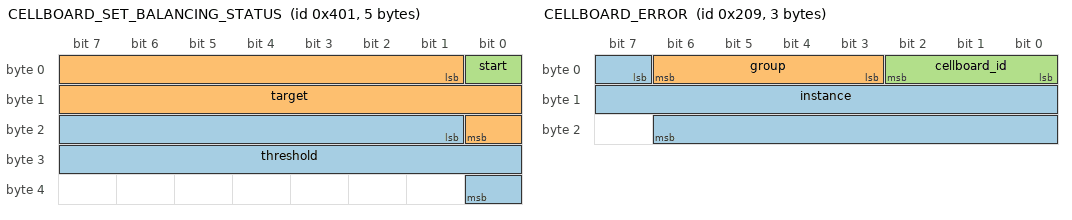
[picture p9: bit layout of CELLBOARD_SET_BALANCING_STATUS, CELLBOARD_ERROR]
BO_ 1025 CELLBOARD_SET_BALANCING_STATUS: 5 Vector__XXX
 SG_ threshold : 17|16@1+ (2.9755092698558025e-06,0.005) [0.005|0.2] "" Vector__XXX
 SG_ target : 1|16@1+ (2.1362630655374995e-05,2.8) [2.8|4.2] "" Vector__XXX
 SG_ start : 0|1@1+ (1,0) [0|1] "" Vector__XXX

BO_ 1577 CELLBOARD_BALANCING_STATUS: 4 Vector__XXX
 SG_ discharging_cell_23 : 28|1@1+ (1,0) [0|1] "" Vector__XXX
 SG_ discharging_cell_22 : 27|1@1+ (1,0) [0|1] "" Vector__XXX
 SG_ discharging_cell_21 : 26|1@1+ (1,0) [0|1] "" Vector__XXX
 SG_ discharging_cell_20 : 25|1@1+ (1,0) [0|1] "" Vector__XXX
 SG_ discharging_cell_19 : 24|1@1+ (1,0) [0|1] "" Vector__XXX
 SG_ discharging_cell_18 : 23|1@1+ (1,0) [0|1] "" Vector__XXX
 SG_ discharging_cell_17 : 22|1@1+ (1,0) [0|1] "" Vector__XXX
 SG_ discharging_cell_16 : 21|1@1+ (1,0) [0|1] "" Vector__XXX
 SG_ discharging_cell_15 : 20|1@1+ (1,0) [0|1] "" Vector__XXX
 SG_ discharging_cell_14 : 19|1@1+ (1,0) [0|1] "" Vector__XXX
 SG_ discharging_cell_13 : 18|1@1+ (1,0) [0|1] "" Vector__XXX
 SG_ discharging_cell_12 : 17|1@1+ (1,0) [0|1] "" Vector__XXX
 SG_ discharging_cell_11 : 16|1@1+ (1,0) [0|1] "" Vector__XXX
 SG_ discharging_cell_10 : 15|1@1+ (1,0) [0|1] "" Vector__XXX
 SG_ discharging_cell_9 : 14|1@1+ (1,0) [0|1] "" Vector__XXX
 SG_ discharging_cell_8 : 13|1@1+ (1,0) [0|1] "" Vector__XXX
 SG_ discharging_cell_7 : 12|1@1+ (1,0) [0|1] "" Vector__XXX
 SG_ discharging_cell_6 : 11|1@1+ (1,0) [0|1] "" Vector__XXX
 SG_ discharging_cell_5 : 10|1@1+ (1,0) [0|1] "" Vector__XXX
 SG_ discharging_cell_4 : 9|1@1+ (1,0) [0|1] "" Vector__XXX
 SG_ discharging_cell_3 : 8|1@1+ (1,0) [0|1] "" Vector__XXX
 SG_ discharging_cell_2 : 7|1@1+ (1,0) [0|1] "" Vector__XXX
 SG_ discharging_cell_1 : 6|1@1+ (1,0) [0|1] "" Vector__XXX
 SG_ discharging_cell_0 : 5|1@1+ (1,0) [0|1] "" Vector__XXX
 SG_ cellboard_id : 2|3@1+ (1,0) [0|7] "" Vector__XXX
 SG_ status : 0|2@1+ (1,0) [0|3] "" Vector__XXX

BO_ 521 CELLBOARD_ERROR: 3 Vector__XXX
 SG_ instance : 7|16@1+ (1,0) [0|65535] "" Vector__XXX
 SG_ group : 3|4@1+ (1,0) [0|15] "" Vector__XXX
 SG_ cellboard_id : 0|3@1+ (1,0) [0|7] "" Vector__XXX

CM_ BO_ 1026 "[LEGACY]: Cellboard's status";
CM_ BO_ 515 "[LEGACY]: Cellboard temperature precalculated values";
CM_ BO_ 1539 "[LEGACY]: Cells' temperatures";
CM_ BO_ 516 "[LEGACY]: Cellboard voltages precalculated values";
CM_ BO_ 1540 "[LEGACY]: Cells' voltages";
CM_ BO_ 16 "[LEGACY]: Set balancing status for cells";
CM_ BO_ 5 "[LEGACY]: Used by Bootcommander";
CM_ BO_ 6 "[LEGACY]: Used by Bootcommander";
CM_ BO_ 7 "[LEGACY]: Used by Bootcommander";
CM_ BO_ 8 "[LEGACY]: Used by Bootcommander";
CM_ BO_ 9 "[LEGACY]: Used by Bootcommander";
CM_ BO_ 10 "[LEGACY]: Used by Bootcommander";
CM_ BO_ 11 "[LEGACY]: Used by Bootcommander";
CM_ BO_ 12 "[LEGACY]: Used by Bootcommander";
CM_ BO_ 13 "[LEGACY]: Used by Bootcommander";
CM_ BO_ 14 "[LEGACY]: Used by Bootcommander";
CM_ BO_ 15 "[LEGACY]: Used by Bootcommander";
CM_ BO_ 0 "Start or stop the actual flash procedure, need a request first";
CM_ BO_ 1 "Flash data transmitted from the master to the cellboards";
CM_ BO_ 2 "Flash data received by the master from the cellboards";
CM_ BO_ 3 "Cellboard flash procedure start request";
CM_ BO_ 4 "Cellboard flash procedure ACK";
CM_ BO_ 1537 "Message used to check if the communication between nodes in the network is working correctly";
CM_ BO_ 1545 "Cellboard version: build-time timestamp and canlib build-time timestamp";
CM_ BO_ 513 "Cellboard internal FSM status";
CM_ BO_ 1553 "Cellboard cells voltages in V";
CM_ BO_ 1561 "Cellboard cells temperatures in Â°C";
CM_ BO_ 1569 "Cellboard discharge resistor temperatures in Â°C";
CM_ BO_ 1025 "Start or stop the balancing procedure, if started needs to be sent continuously";
CM_ BO_ 1577 "Info about the cells that are currently discharging";
CM_ BO_ 521 "Info regarding the error which has occured";
BA_DEF_ BU_  "Manufacturer" STRING ;
BA_DEF_ BU_  "ILUsed" ENUM  "No","Yes";
BA_DEF_ BO_  "NmMessage" ENUM  "no","yes";
BA_DEF_ BO_  "GenMsgILSupport" ENUM  "No","Yes";
BA_DEF_  "NmBaseAddress" HEX 1024 1087;
BA_DEF_  "BusType" STRING ;
BA_DEF_ BO_  "GenMsgCycleTime" INT 0 1000;
BA_DEF_ BO_  "GenMsgSendType" ENUM  "Cyclic","NotUsed","NotUsed","NotUsed","NotUsed","Cyclic","NotUsed","IfActive","NoMsgSendType","NotUsed","vector_leerstring";
BA_DEF_ SG_  "GenSigSendType" ENUM  "Cyclic","OnWrite","OnWriteWithRepetition","OnChange","OnChangeWithRepetition","IfActive","IfActiveWithRepetition","NoSigSendType","NotUsed","NotUsed","NotUsed","NotUsed","NotUsed";
BA_DEF_ SG_  "GenSigStartValue" FLOAT 0 100000000000;
BA_DEF_DEF_  "Manufacturer" "Isabellenhuette";
BA_DEF_DEF_  "ILUsed" "Yes";
BA_DEF_DEF_  "NmMessage" "no";
BA_DEF_DEF_  "GenMsgILSupport" "Yes";
BA_DEF_DEF_  "NmBaseAddress" 1024;
BA_DEF_DEF_  "BusType" "CAN";
BA_DEF_DEF_  "GenMsgCycleTime" 0;
BA_DEF_DEF_  "GenMsgSendType" "NoMsgSendType";
BA_DEF_DEF_  "GenSigSendType" "OnWrite";
BA_DEF_DEF_  "GenSigStartValue" 0;
BA_ "GenMsgSendType" BO_ 1320 1;
BA_ "GenSigSendType" SG_ 1320 IVT_Result_Wh 7;
BA_ "GenSigSendType" SG_ 1320 IVT_ID_Result_Wh 7;
BA_ "GenSigStartValue" SG_ 1320 IVT_ID_Result_Wh 7;
BA_ "GenMsgSendType" BO_ 1319 1;
BA_ "GenSigSendType" SG_ 1319 IVT_ID_Result_As 7;
BA_ "GenSigStartValue" SG_ 1319 IVT_ID_Result_As 6;
BA_ "GenMsgSendType" BO_ 1318 1;
BA_ "GenSigSendType" SG_ 1318 IVT_ID_Result_W 7;
BA_ "GenSigStartValue" SG_ 1318 IVT_ID_Result_W 5;
BA_ "GenMsgSendType" BO_ 1297 1;
BA_ "GenSigStartValue" SG_ 1297 _A7_Resp_TriggerMode_WH 2;
BA_ "GenSigStartValue" SG_ 1297 _A6_Resp_TriggerMode_As 2;
BA_ "GenSigStartValue" SG_ 1297 _A5_Resp_TriggerMode_W 2;
BA_ "GenSigStartValue" SG_ 1297 _A4_Resp_TriggerMode_T 2;
BA_ "GenSigStartValue" SG_ 1297 _A0_Resp_TriggerMode_I 2;
BA_ "GenMsgSendType" BO_ 1317 1;
BA_ "GenSigSendType" SG_ 1317 IVT_ID_Result_T 7;
BA_ "GenSigStartValue" SG_ 1317 IVT_ID_Result_T 4;
BA_ "GenMsgSendType" BO_ 1316 1;
BA_ "GenSigSendType" SG_ 1316 IVT_ID_Result_U3 7;
BA_ "GenSigStartValue" SG_ 1316 IVT_ID_Result_U3 3;
BA_ "GenMsgSendType" BO_ 1315 1;
BA_ "GenSigSendType" SG_ 1315 IVT_ID_Result_U2 7;
BA_ "GenSigStartValue" SG_ 1315 IVT_ID_Result_U2 2;
BA_ "GenMsgSendType" BO_ 1314 1;
BA_ "GenSigSendType" SG_ 1314 IVT_Result_U1 7;
BA_ "GenSigSendType" SG_ 1314 IVT_ID_Result_U1 7;
BA_ "GenSigStartValue" SG_ 1314 IVT_ID_Result_U1 1;
BA_ "GenMsgSendType" BO_ 1313 1;
BA_ "GenSigSendType" SG_ 1313 IVT_Result_I 7;
BA_ "GenSigSendType" SG_ 1313 IVT_ID_Result_I 7;
BA_ "GenMsgSendType" BO_ 1041 7;
BA_ "NmMessage" BO_ 1041 1;
BA_ "GenSigStartValue" SG_ 1041 _27_Conf_TriggerMode_WH 2;
BA_ "GenSigStartValue" SG_ 1041 _26_Conf_TriggerMode_As 2;
BA_ "GenSigStartValue" SG_ 1041 _25_Conf_TriggerMode_W 2;
BA_ "GenSigStartValue" SG_ 1041 _24_Conf_TriggerMode_T 2;
BA_ "GenSigStartValue" SG_ 1041 _20_Conf_TriggerMode_I 2;
BA_ "GenMsgCycleTime" BO_ 0 200;
BA_ "GenMsgCycleTime" BO_ 1545 1000;
BA_ "GenMsgCycleTime" BO_ 513 20;
BA_ "GenMsgCycleTime" BO_ 1553 50;
BA_ "GenMsgCycleTime" BO_ 1561 50;
BA_ "GenMsgCycleTime" BO_ 1569 50;
BA_ "GenMsgCycleTime" BO_ 1025 200;
BA_ "GenMsgCycleTime" BO_ 1577 50;
BA_ "GenMsgCycleTime" BO_ 521 20;
VAL_ 1320 IVT_ID_Result_Wh 7 "Vt_Result_Wh" ;
VAL_ 1319 IVT_ID_Result_As 6 "Vt_Result_As" ;
VAL_ 1318 IVT_ID_Result_W 5 "Vt_Result_W" ;
VAL_ 1297 _B9_Resp_Device_V_supply 1 "12__24_V_nominal_supply_voltage" ;
VAL_ 1297 _B9_Resp_Device_Com 2 "CAN_2___not_terminated" 1 "CAN_1___terminated" 0 "none" ;
VAL_ 1297 _B9_Resp_Device_TOI 3 "I" ;
VAL_ 1297 _B9_Resp_Device_Voltage_chan 3 "3_Channels" 0 "0_Channels" ;
VAL_ 1297 _B4_Resp_Startup_Mode 1 "Run" 0 "Stop" ;
VAL_ 1297 _B9_Resp_Device_current 2500 "2500_A" 1000 "1000_A" 500 "500_A" 300 "300_A" 100 "100_A" ;
VAL_ 1297 _B4_Resp_Actual_Mode 1 "RUN" 0 "STOP" ;
VAL_ 1297 _A7_Resp_TriggerMode_WH 2 "CYCLIC" 1 "TRIGGERED" 0 "DISABLED" ;
VAL_ 1297 _A6_Resp_TriggerMode_As 2 "CYCLIC" 1 "TRIGGERED" 0 "DISABLED" ;
VAL_ 1297 _A5_Resp_TriggerMode_W 2 "CYCLIC" 1 "TRIGGERED" 0 "DISABLED" ;
VAL_ 1297 _A4_Resp_TriggerMode_T 2 "CYCLIC" 1 "TRIGGERED" 0 "DISABLED" ;
VAL_ 1297 _A3_Resp_TriggerMode_U3 2 "CYCLIC" 1 "TRIGGERED" 0 "DISABLED" ;
VAL_ 1297 _A2_Resp_TriggerMode_U2 2 "CYCLIC" 1 "TRIGGERED" 0 "DISABLED" ;
VAL_ 1297 _A1_Resp_TriggerMode_U1 2 "CYCLIC" 1 "TRIGGERED" 0 "DISABLED" ;
VAL_ 1297 _A0_Resp_TriggerMode_I 2 "CYCLIC" 1 "TRIGGERED" 0 "DISABLED" ;
VAL_ 1297 _B9_Resp_Device_type 2 "IVT_S" 1 "IVT_Mod" ;
VAL_ 1297 _B0_Resp_Reset_Item 554 "Reset_temp_minimum" 553 "Reset_temp_maximum" 552 "Reset_U3_minimum" 551 "Reset_U3_maximum" 550 "Reset_U2_minimum" 549 "Reset_U2_maximum" 548 "Reset_U1_minimum" 547 "Reset_U1_maximum" 546 "Reset_Current_minimum" 545 "Reset_Current_maximum" 540 "Reset_Run_overcur_neg_activated" 539 "Reset_Run_overcur_pos_activated" 538 "Reset_Run_temp_out_spec_limits" 537 "Reset_Run_temp_in_spec_limits" 536 "Reset_Run_volt_3_out_spec_limits" 535 "Reset_Run_volt_3_in_spec_limits" 534 "Reset_Run_volt_2_out_spec_limits" 533 "Reset_Run_volt_2_in_spec_limits" 532 "Reset_Run_volt_1_out_spec_limits" 531 "Reset_Run_volt_1_in_spec_limits" 530 "Reset_Run_cur_out_spec_limits" 529 "Reset_Run_cur_in_spec_limits" 528 "Reset_Runtime_overall" 518 "Reset_Energy_counter_discharging" 517 "Reset_Energy_counter_charging" 516 "Reset_Energy_counter_overall" 515 "Reset_Ah_counter_discharging" 514 "Reset_Ah_counter_charging" 513 "Reset_Ah_counter_overall" 512 "Reset_all_Logdata_Since_Reset" 272 "Reset_Reset_EMC" 271 "Reset_Reset_Watchdog" 270 "Reset_illegal_opcode" 269 "Reset_ADC_Clock" 268 "Reset_eeprom_rw" 267 "Reset_overcurrent_detection" 266 "Reset_configuration" 265 "Reset_system_init" 264 "Reset_system_clock" 263 "Reset_power_failure" 262 "Reset_undertemp" 261 "Reset_overtemp" 260 "Reset_CAN_bus_transmit_Data" 259 "Reset_CAN_bus_receive_Data" 258 "Reset_Parameter_CRC" 257 "Reset_Code_CRC" 256 "Reset_all_System_errors" 15 "Reset_calibration_data_" 14 "Reset_ntc_I_OpenCircuit" 13 "Reset_ntc_h_OpenCircuit" 12 "Reset_voltage_measU3_OpenCircuit" 11 "Reset_voltage_measU2_OpenCircuit" 10 "Reset_voltage_measU1_OpenCircuit" 9 "Reset_current_measI1_OpenCircuit" 8 "Reset_thermal_EMF_correction" 7 "Reset_error_current_implausible" 6 "Reset_error_Vref" 5 "Reset_error_Underflow_ADC_ch2" 4 "Reset_error_Overflow_ADC_ch2" 3 "Reset_error_Underflow_ADC_ch1" 2 "Reset_error_Overflow_ADC_ch1" 1 "Reset_error_ADC_interrupt" 0 "Reset_all_measurement_errors" ;
VAL_ 1297 _83_Resp_LogData_Item 42 "Resp_temp_minimum" 41 "Resp_temp_maxmimum" 40 "Resp_U3_minimum" 39 "Resp_U3_maximum" 38 "Resp_U2_minimum" 37 "Resp_U2_maxmimum" 36 "Resp_U1_minimum" 35 "Resp_U1_maximum" 34 "Resp_current_minimum" 33 "Resp_current_maximum" 28 "Resp_oc_negative_activated" 27 "Resp_oc_positive_activated" 26 "Resp_run_temp_out_spec_limits" 25 "Resp_run_temp_in_spec_limits" 24 "Resp_run_volt_3_out_spec_limits" 23 "Resp_run_volt_3_in_spec_limits" 22 "Resp_run_volt_2_out_spec_limits" 21 "Resp_run_volt_2_in_spec_limits" 20 "Resp_run_volt_1_out_spec_limits" 19 "Resp_run_volt_1_in_spec_limits" 18 "Resp_run_cur_out_spec_limits" 17 "Resp_run_cur_in_spec_limits" 16 "Resp_run_overall" 6 "Resp_energy_counter_discharging" 5 "Resp_energy_counter_charging" 4 "Resp_energy_counter_overall" 3 "Resp_Ah_counter_discharging" 2 "Resp_Ah_counter_charging" 1 "Resp_Ah_counter_overall" 0 "Response_all_Logdata_SinceReset" ;
VAL_ 1297 _82_Resp_AllLogData_Item 42 "Resp_temp_minimum" 41 "Resp_temp_maxmimum" 40 "Resp_U3_minimum" 39 "Resp_U3_maximum" 38 "Resp_U2_minimum" 37 "Resp_U2_maxmimum" 36 "Resp_U1_minimum" 35 "Resp_U1_maximum" 34 "Resp_current_minimum" 33 "Resp_current_maximum" 28 "Resp_oc_negative_activated" 27 "Resp_oc_positive_activated" 26 "Resp_run_temp_out_spec_limits" 25 "Resp_run_temp_in_spec_limits" 24 "Resp_run_volt_3_out_spec_limits" 23 "Resp_run_volt_3_in_spec_limits" 22 "Resp_run_volt_2_out_spec_limits" 21 "Resp_run_volt_2_in_spec_limits" 20 "Resp_run_volt_1_out_spec_limits" 19 "Resp_run_volt_1_in_spec_limits" 18 "Resp_run_cur_out_spec_limits" 17 "Resp_run_cur_in_spec_limits" 16 "Resp_run_overall" 6 "Resp_energy_counter_discharging" 5 "Resp_energy_counter_charging" 4 "Resp_energy_counter_overall" 3 "Resp_Ah_counter_discharging" 2 "Resp_Ah_counter_charging" 1 "Resp_Ah_counter_overall" 0 "Response_on_Overall_Logdata" ;
VAL_ 1297 _81_Resp_SystemError_Item 16 "Resp_error_Reset_EMC" 15 "Resp_error_Reset_Watchdog" 14 "Resp_error_Reset_illegal_opcode" 13 "Resp_error_ADC_Clock" 12 "Resp_error_eeprom_rw" 11 "Resp_error_Overcurrent_detection" 10 "Resp_error_Configuration" 9 "Resp_error_System_Init" 8 "Resp_error_System_Clock" 7 "Resp_error_Power_failure" 6 "Resp_error_Undertemp" 5 "Resp_error_Overtemp" 4 "Resp_error_CAN_bus_transmit_Data" 3 "Resp_error_CAN_bus_receive_Data" 2 "Resp_error_Parameter_CRC" 1 "Resp_error_code_CRC" 0 "Resonse_all_SystemErrors" ;
VAL_ 1297 _80_Resp_MeasError_Item 15 "Resp_error_calibration_data" 14 "Resp_error_ntc_I_OpenCirc" 13 "Resp_error_ntc_h_OpenCirc" 12 "Resp_error_meas_U3_OpenCirc" 11 "Resp_error_meas_U2_OpenCirc" 10 "Resp_error_meas_U1_OpenCirc" 9 "Resp_error_meas_I1_OpenCirc" 8 "Resp__error_therm_EMF_correction" 7 "Resp_error_cur_meas_implausible" 6 "Resp_error_Vref" 5 "Resp_error_Underflow_ADC_ch_2" 4 "Resp_error_Overflow_ADC_ch_2" 3 "Resp_error_Underflow_ADC_ch_1" 2 "Reso_error_Overflow_ADC_ch_1" 1 "Resp_error_ADC_interrupt" 0 "Resonse_all_meas_errors" ;
VAL_ 1297 IVT_ID_Response 255 "Resp_Cmd_Wrong_Command" 191 "Resp_Get_Set_ALIVE" 188 "Resp_Get_Set_ArtNr" 187 "Resp_Get_Set_Serialnumber" 186 "Resp_Get_Set_SW_VERSION" 185 "Resp_Get_Set_DEVICE_ID" 182 "Resp_Get_Set_THRESHOLD_NEG" 181 "Resp_Get_Set_THRESHOLD_POS" 180 "Resp_Get_Set_MODE" 179 "Resp_Get_Set_OC_TEST_TIME" 178 "Resp_Get_Set_STORE" 177 "Resp_Get_Set_TRIGGER" 176 "Resp_Get_Set_Reset_Error_Logdata" 167 "Resp_Config_Result_Wh" 166 "Resp_Config_Result_As" 165 "Resp_Config_Result_W" 164 "Resp_Config_Result_T" 163 "Resp_Config_Result_U3" 162 "Resp_Config_Result_U2" 161 "Resp_Config_Result_U1" 160 "Resp_Config_Result_I" 159 "Resp_CAN_ID_Response" 157 "Resp_CAN_ID_Command" 151 "Resp_CAN_ID_Res_Wh" 150 "Resp_CAN_ID_Res_As" 149 "Resp_CAN_ID_Res_W" 144 "Resp_CAN_ID_Res_I" 148 "Resp_CAN_ID_Res_T" 147 "Resp_CAN_ID_Res_U3" 146 "Resp_CAN_ID_Res_U2" 145 "Resp_CAN_ID_Res_U1" 131 "Resp_Error_Log_Logdata_Since_Res" 130 "Resp_Error_Log_Overall_Logdata" 129 "Resp_Error_Log_System_Error" 128 "Resp_Error_Log_Measurement_Error" ;
VAL_ 1317 IVT_ID_Result_T 4 "Vt_Result_T" ;
VAL_ 1316 IVT_ID_Result_U3 3 "Vt_Result_U3" ;
VAL_ 1315 IVT_ID_Result_U2 2 "Vt_Result_U2" ;
VAL_ 1314 IVT_ID_Result_U1 1 "Vt_Result_U1" ;
VAL_ 1313 IVT_ID_Result_I 0 "Vt_Result_I" ;
VAL_ 1041 _34_Startup_Mode 1 "START" 0 "STOP" ;
VAL_ 1041 _34_Actual_Mode 1 "START" 0 "STOP" ;
VAL_ 1041 _27_Conf_TriggerMode_WH 2 "CYCLIC" 1 "TRIGGERED" 0 "DISABLED" ;
VAL_ 1041 _26_Conf_TriggerMode_As 2 "CYCLIC" 1 "TRIGGERED" 0 "DISABLED" ;
VAL_ 1041 _25_Conf_TriggerMode_W 2 "CYCLIC" 1 "TRIGGERED" 0 "DISABLED" ;
VAL_ 1041 _24_Conf_TriggerMode_T 2 "CYCLIC" 1 "TRIGGERED" 0 "DISABLED" ;
VAL_ 1041 _23_Conf_TriggerMode_U3 2 "CYCLIC" 1 "TRIGGERED" 0 "DISABLED" ;
VAL_ 1041 _22_Conf_TriggerMode_U2 2 "CYCLIC" 1 "TRIGGERED" 0 "DISABLED" ;
VAL_ 1041 _21_Conf_TriggerMode_U1 2 "CYCLIC" 1 "TRIGGERED" 0 "DISABLED" ;
VAL_ 1041 _20_Conf_TriggerMode_I 2 "CYCLIC" 1 "TRIGGERED" 0 "DISABLED" ;
VAL_ 1041 _43_Get_LogData_Item 42 "Get_Temperature_minimum" 41 "Get_Temperature_maximum" 40 "Get_U3_minimum" 39 "Get_U3_maxmimum_" 38 "Get_U2_minimum" 37 "Get_U2_maximum" 36 "Get_U1_minimum" 35 "Get_U1_maxmimum" 34 "Get_current_minimum" 33 "Get_current_maximum" 28 "Get_run_overcur_neg_activated" 27 "Get_run_overcur_pos_activated" 26 "Get_run_temp_out_spec_limits" 25 "Get_run_temp_in_spec_limits" 24 "Get_run_volt3_out_spec_limits" 23 "Get_run_volt3_in_spec_limits" 22 "Get_run_volt2_out_spec_limits" 21 "Get_run_volt2_in_spec_limits" 20 "Get_run_volt1_out_spec_limits" 19 "Get_run_volt1_in_spec_limits" 18 "Get_run_cur_out_spec_limits" 17 "Get_Run_cur_in_spec_limits" 16 "Get_Runtime_overall" 6 "Get_Energy_counter_discharging" 5 "Get_Energy_counter_charging" 4 "Get_Energy_counter_overall" 3 "Get_Ah_counter_discharging" 2 "Get_Ah_counter_charging" 1 "Get_Ah_counter_overall" 0 "Get_Overall_Logdata" ;
VAL_ 1041 _42_Get_AllLogData_Item 42 "Get_Temperature_minimum" 41 "Get_Temperature_maximum" 40 "Get_U3_minimum" 39 "Get_U3_maxmimum_" 38 "Get_U2_minimum" 37 "Get_U2_maximum" 36 "Get_U1_minimum" 35 "Get_U1_maxmimum" 34 "Get_current_minimum" 33 "Get_current_maximum" 28 "Get_run_overcur_neg_activated" 27 "Get_run_overcur_pos_activated" 26 "Get_run_temp_out_spec_limits" 25 "Get_run_temp_in_spec_limits" 24 "Get_run_volt3_out_spec_limits" 23 "Get_run_volt3_in_spec_limits" 22 "Get_run_volt2_out_spec_limits" 21 "Get_run_volt2_in_spec_limits" 20 "Get_run_volt1_out_spec_limits" 19 "Get_run_volt1_in_spec_limits" 18 "Get_run_cur_out_spec_limits" 17 "Get_Run_cur_in_spec_limits" 16 "Get_Runtime_overall" 6 "Get_Energy_counter_discharging" 5 "Get_Energy_counter_charging" 4 "Get_Energy_counter_overall" 3 "Get_Ah_counter_discharging" 2 "Get_Ah_counter_charging" 1 "Get_Ah_counter_overall" 0 "Get_Overall_Logdata" ;
VAL_ 1041 _41_Get_SystemError_Item 16 "Get_error_reset_EMC" 15 "Get_error_reset_Watchdog" 14 "Get_error_reset_illegal_opcode" 13 "Get_error_ADC_clock" 12 "Get_error_eeprom_rw" 11 "Get_error_overcurrent_detection" 10 "Get_error_configuration" 9 "Get_error_system_init" 8 "Get_error_system_clock" 7 "Get_error_power_failure" 6 "Get_error_undertemp" 5 "Get_error_overtemp" 4 "Get_error_CAN_bus_transmit_Data" 3 "Get_error_CAN__bus_receive_Data" 2 "Get_error_Code_Parameter_CRC" 1 "Get_error_Code_CRC" 0 "Get_all_System_errors" ;
VAL_ 1041 _40_Get_MeasError_Item 15 "Get_error_calibration_data" 14 "Get_error_ntc_I_OpenCirc" 13 "Get_error_ntc_h_OpenCirc" 12 "Get_error_volt_meas_U3_OpenCirc" 11 "Get_error_volt_meas_U2_OpenCirc" 10 "Get_error_volt_meas_U1_OpenCirc" 9 "Get_error_cur_meas_I1_OpenCirc" 8 "Get_error_thermal_EMF_correction" 7 "Get_error_cur_meas_implausible" 6 "Get_error_Vref" 5 "Get_error_Underflow_ADC_ch_2" 4 "Get_error_Overflow_ADC_ch_2" 3 "Get_error_Underflow_ADC_ch_1" 2 "Get_error_Overflow_ADC_ch_1" 1 "Get_error_ADC_interrupt" 0 "Get_all_meas_Errors" ;
VAL_ 1041 _3A_RESTART_to_Bitrate 8 "250k" 4 "500k" 2 "1000k" ;
VAL_ 1041 _30_Reset_Item 554 "Reset_temp_minimum" 553 "Reset_temp_maximum" 552 "Reset_U3_minimum" 551 "Reset_U3_maximum" 550 "Reset_U2_minimum" 549 "Reset_U2_maximum" 548 "Reset_U1_minimum" 547 "Reset_U1_maximum" 546 "Reset_Current_minimum" 545 "Reset_Current_maximum" 540 "Reset_Run_overcur_neg_activated" 539 "Reset_Run_overcur_pos_activated" 538 "Reset_Run_temp_out_spec_limits" 537 "Reset_Run_temp_in_spec_limits" 536 "Reset_Run_volt_3_out_spec_limits" 535 "Reset_Run_volt_3_in_spec_limits" 534 "Reset_Run_volt_2_out_spec_limits" 533 "Reset_Run_volt_2_in_spec_limits" 532 "Reset_Run_volt_1_out_spec_limits" 531 "Reset_Run_volt_1_in_spec_limits" 530 "Reset_Run_cur_out_spec_limits" 529 "Reset_Run_cur_in_spec_limits" 528 "Reset_Runtime_overall" 518 "Reset_Energy_counter_discharging" 517 "Reset_Energy_counter_charging" 516 "Reset_Energy_counter_overall" 515 "Reset_Ah_counter_discharging" 514 "Reset_Ah_counter_charging" 513 "Reset_Ah_counter_overall" 512 "Reset_all_Logdata_Since_Reset" 272 "Reset_Reset_EMC" 271 "Reset_Reset_Watchdog" 270 "Reset_illegal_opcode" 269 "Reset_ADC_Clock" 268 "Reset_eeprom_rw" 267 "Reset_overcurrent_detection" 266 "Reset_configuration" 265 "Reset_system_init" 264 "Reset_system_clock" 263 "Reset_power_failure" 262 "Reset_undertemp" 261 "Reset_overtemp" 260 "Reset_CAN_bus_transmit_Data" 259 "Reset_CAN_bus_receive_Data" 258 "Reset_Parameter_CRC" 257 "Reset_Code_CRC" 256 "Reset_all_System_errors" 15 "Reset_calibration_data_" 14 "Reset_ntc_I_OpenCircuit" 13 "Reset_ntc_h_OpenCircuit" 12 "Reset_voltage_measU3_OpenCircuit" 11 "Reset_voltage_measU2_OpenCircuit" 10 "Reset_voltage_measU1_OpenCircuit" 9 "Reset_current_measI1_OpenCircuit" 8 "Reset_thermal_EMF_correction" 7 "Reset_error_current_implausible" 6 "Reset_error_Vref" 5 "Reset_error_Underflow_ADC_ch2" 4 "Reset_error_Overflow_ADC_ch2" 3 "Reset_error_Underflow_ADC_ch1" 2 "Reset_error_Overflow_ADC_ch1" 1 "Reset_error_ADC_interrupt" 0 "Reset_all_measurement_errors" ;
VAL_ 1041 IVT_ID_Cmd 124 "Get_cmd_and_info_ArtNr" 123 "Get_cmd_and_info_SN" 122 "Get_cmd_and_info_SW_Version" 121 "Get_cmd_and_info_DEVICE_ID" 118 "Get_cmd_and_info_THRESHOLD_NEG" 117 "Get_cmd_and_info_THRESHOLD_POS" 116 "Get_cmd_and_info_MODE" 115 "Get_cmd_and_info_OC_TEST_TIME" 103 "Get_Config_Res_Wh" 102 "Get_Config_Res_As" 101 "Get_Config_Res_W" 100 "Get_Config_Res_T" 99 "Get_Config_Res_U3" 98 "Get_Config_Res_U2" 97 "Get_Config_Res_U1" 96 "Get_Config_Res_I" 95 "Get_CAN_ID_Response" 93 "Get_CAN_ID_Command" 87 "Get_CAN_ID_Res_Wh" 86 "Get_CAN_ID_Res_As" 85 "Get_CAN_ID_Res_W" 84 "Get_CAN_ID_Res_T" 83 "Get_CAN_ID_Res_U3" 82 "Get_CAN_ID_Res_U2" 81 "Get_CAN_ID_Res_U1" 80 "Get_CAN_ID_Res_I" 67 "Get_Logdata_Since_Reset" 66 "Get_Overall_Logdata" 65 "Get_System_Errors" 64 "Get_Measurement_Errors" 63 "Set_RESTART" 61 "Set_RESTART_to_default" 58 "RESTART_to_Bitrate" 54 "Set_THRESHOLD_neg" 53 "Set_THRESHOLD_pos" 32 "Set_MODE_Result_I" 16 "Set_CAN_ID_Result_I" 52 "Set_MODE" 51 "START_OC_TEST" 50 "STORE" 49 "TRIGGER" 48 "Reset_Err_Log" 39 "Set_MODE_Result_Wh" 38 "Set_MODE_Result_As" 37 "Set_MODE_Result_W" 23 "Set_CAN_ID_Result_Wh" 22 "Set_CAN_ID_Result_As" 21 "Set_CAN_ID_Result_W" 20 "Set_CAN_ID_Result_T" 35 "Set_MODE_Result_U3" 31 "Set_CAN_ID_Response" 29 "Set_CAN_ID_Cmd" 19 "Set_CAN_ID_Result_U3" 18 "Set_CAN_ID_Result_U2" 36 "Set_MODE_Result_T" 34 "Set_MODE_Result_U2" 33 "Set_MODE_Result_U1" 17 "Set_CAN_ID_Result_U1" ;
VAL_ 1026 balancing_status 0 "OFF" 1 "DISCHARGE" ;
VAL_ 1026 cellboard_id 0 "CELLBOARD_0" 1 "CELLBOARD_1" 2 "CELLBOARD_2" 3 "CELLBOARD_3" 4 "CELLBOARD_4" 5 "CELLBOARD_5" ;
VAL_ 515 cellboard_id 0 "CELLBOARD_0" 1 "CELLBOARD_1" 2 "CELLBOARD_2" 3 "CELLBOARD_3" 4 "CELLBOARD_4" 5 "CELLBOARD_5" ;
VAL_ 1539 cellboard_id 0 "CELLBOARD_0" 1 "CELLBOARD_1" 2 "CELLBOARD_2" 3 "CELLBOARD_3" 4 "CELLBOARD_4" 5 "CELLBOARD_5" ;
VAL_ 516 cellboard_id 0 "CELLBOARD_0" 1 "CELLBOARD_1" 2 "CELLBOARD_2" 3 "CELLBOARD_3" 4 "CELLBOARD_4" 5 "CELLBOARD_5" ;
VAL_ 1540 cellboard_id 0 "CELLBOARD_0" 1 "CELLBOARD_1" 2 "CELLBOARD_2" 3 "CELLBOARD_3" 4 "CELLBOARD_4" 5 "CELLBOARD_5" ;
VAL_ 16 balancing_status 0 "OFF" 1 "DISCHARGE" ;
VAL_ 0 cellboard_id 0 "CELLBOARD_0" 1 "CELLBOARD_1" 2 "CELLBOARD_2" 3 "CELLBOARD_3" 4 "CELLBOARD_4" 5 "CELLBOARD_5" ;
VAL_ 3 cellboard_id 0 "cellboard_0" 1 "cellboard_1" 2 "cellboard_2" 3 "cellboard_3" 4 "cellboard_4" 5 "cellboard_5" ;
VAL_ 4 cellboard_id 0 "cellboard_0" 1 "cellboard_1" 2 "cellboard_2" 3 "cellboard_3" 4 "cellboard_4" 5 "cellboard_5" ;
VAL_ 1537 cellboard_id 0 "cellboard_0" 1 "cellboard_1" 2 "cellboard_2" 3 "cellboard_3" 4 "cellboard_4" 5 "cellboard_5" ;
VAL_ 1545 cellboard_id 0 "cellboard_0" 1 "cellboard_1" 2 "cellboard_2" 3 "cellboard_3" 4 "cellboard_4" 5 "cellboard_5" ;
VAL_ 513 status 0 "init" 1 "idle" 2 "fatal" 3 "flash" 4 "discharge" 5 "cooldown" ;
VAL_ 513 cellboard_id 0 "cellboard_0" 1 "cellboard_1" 2 "cellboard_2" 3 "cellboard_3" 4 "cellboard_4" 5 "cellboard_5" ;
VAL_ 1553 cellboard_id 0 "cellboard_0" 1 "cellboard_1" 2 "cellboard_2" 3 "cellboard_3" 4 "cellboard_4" 5 "cellboard_5" ;
VAL_ 1561 cellboard_id 0 "cellboard_0" 1 "cellboard_1" 2 "cellboard_2" 3 "cellboard_3" 4 "cellboard_4" 5 "cellboard_5" ;
VAL_ 1569 cellboard_id 0 "cellboard_0" 1 "cellboard_1" 2 "cellboard_2" 3 "cellboard_3" 4 "cellboard_4" 5 "cellboard_5" ;
VAL_ 1577 cellboard_id 0 "cellboard_0" 1 "cellboard_1" 2 "cellboard_2" 3 "cellboard_3" 4 "cellboard_4" 5 "cellboard_5" ;
VAL_ 1577 status 0 "stopped" 1 "paused" 2 "running" ;
VAL_ 521 group 0 "post" 1 "under_voltage" 2 "over_voltage" 3 "under_temperature_cells" 4 "over_temperature_cells" 5 "under_temperature_discharge" 6 "over_temperature_discharge" 7 "can_communication" 8 "flash" 9 "bms_monitor_communication" 10 "open_wire" ;
VAL_ 521 cellboard_id 0 "cellboard_0" 1 "cellboard_1" 2 "cellboard_2" 3 "cellboard_3" 4 "cellboard_4" 5 "cellboard_5" ;
